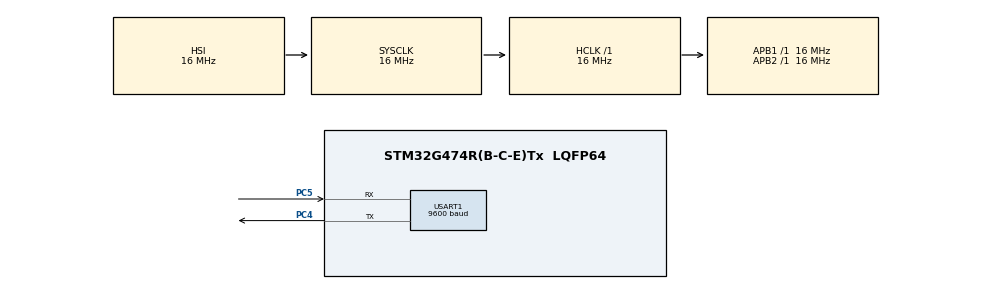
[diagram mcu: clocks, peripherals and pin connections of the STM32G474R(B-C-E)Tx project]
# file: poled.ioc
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Mcu.Family=STM32G4
Mcu.Name=STM32G474R(B-C-E)Tx
Mcu.Package=LQFP64
NVIC.PriorityGroup=NVIC_PRIORITYGROUP_4
PA13.Mode=Serial_Wire
PA13.Signal=SYS_JTMS-SWDIO
PA14.Mode=Serial_Wire
PA14.Signal=SYS_JTCK-SWCLK
PC4.Mode=Asynchronous
PC4.Signal=USART1_TX
PC5.Mode=Asynchronous
PC5.Signal=USART1_RX
ProjectManager.HeapSize=0x200
ProjectManager.StackSize=0x400
ProjectManager.TargetToolchain=MDK-ARM V5.32
RCC.AHBFreq_Value=16000000
RCC.APB1Freq_Value=16000000
RCC.APB1TimFreq_Value=16000000
RCC.APB2Freq_Value=16000000
RCC.APB2TimFreq_Value=16000000
RCC.CortexFreq_Value=16000000
RCC.EXTERNAL_CLOCK_VALUE=12288000
RCC.HCLKFreq_Value=16000000
RCC.HSE_VALUE=8000000
RCC.HSI48_VALUE=48000000
RCC.HSI_VALUE=16000000
RCC.LSE_VALUE=32768
RCC.SYSCLKFreq_VALUE=16000000
RCC.USBFreq_Value=64000000
RCC.VCOOutputFreq_Value=128000000
USART1.BaudRate=9600
USART1.VirtualMode-Asynchronous=VM_ASYNC
VP_SYS_VS_DBSignals.Mode=DisableDeadBatterySignals
board=custom

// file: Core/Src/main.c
/* USER CODE BEGIN Header */
/**
  ******************************************************************************
  * @file           : main.c
  * @brief          : Main program body
  ******************************************************************************
  * @attention
  *
  * Copyright (c) 2025 STMicroelectronics.
  * All rights reserved.
  *
  * This software is licensed under terms that can be found in the LICENSE file
  * in the root directory of this software component.
  * If no LICENSE file comes with this software, it is provided AS-IS.
  *
  ******************************************************************************
  */
/* USER CODE END Header */
#include "main.h"
#include "usart.h"
#include "gpio.h"

/* USER CODE BEGIN Includes */
#include "math.h"
#include <stdio.h>

/* USER CODE END Includes */

void SystemClock_Config(void);

/* USER CODE BEGIN 0 */
int fputc(int ch, FILE *f){
uint8_t temp[1] = {ch};
HAL_UART_Transmit(&huart1, temp, 1, 2);//huart1��Ҫ������������޸�
return ch;
}

////////////////////////////////////////////////////////////////////////////////////////////
int i;
int test_num = 0;
float test_float = 0;
void HMI_send_string(char* name, char* showdata)
{
    // printf("t0.txt=\"%d\"\xff\xff\xff", num);
    printf("%s=\"%s\"\xff\xff\xff", name, showdata);
}
void HMI_send_number(char* name, int num)
{
    // printf("t0.txt=\"%d\"\xff\xff\xff", num);
    printf("%s=%d\xff\xff\xff", name, num);
}
void HMI_send_float(char* name, float num)
{
    // printf("t0.txt=\"%d\"\xff\xff\xff", num);
    printf("%s=%d\xff\xff\xff", name, (int)(num * 100));
}
void HMI_Wave(char* name, int ch, int val)
{
    printf("add %s,%d,%d\xff\xff\xff", name, ch, val);
}
/* USER CODE END 0 */

int main(void)
{

  /* MCU Configuration--------------------------------------------------------*/

  /* Reset of all peripherals, Initializes the Flash interface and the Systick. */
  HAL_Init();

  /* Configure the system clock */
  SystemClock_Config();

  /* Initialize all configured peripherals */
  MX_GPIO_Init();
  MX_USART1_UART_Init();

  /* Infinite loop */
  while (1)
  {
	HMI_send_string("t0.txt", "1234");

	  int sin_data[255];
    for (i = 0; i < 255; i++)
		{
			sin_data[i] = (int)((sin((i + 1) * 3.14 / 50) + 1) * 90);
			HMI_Wave("s0.id", 0, sin_data[i]);
		}

  }
}

void SystemClock_Config(void)
{
  RCC_OscInitTypeDef RCC_OscInitStruct = {0};
  RCC_ClkInitTypeDef RCC_ClkInitStruct = {0};

  /** Configure the main internal regulator output voltage
  */
  HAL_PWREx_ControlVoltageScaling(PWR_REGULATOR_VOLTAGE_SCALE1);

  /** Initializes the RCC Oscillators according to the specified parameters
  * in the RCC_OscInitTypeDef structure.
  */
  RCC_OscInitStruct.OscillatorType = RCC_OSCILLATORTYPE_HSI;
  RCC_OscInitStruct.HSIState = RCC_HSI_ON;
  RCC_OscInitStruct.HSICalibrationValue = RCC_HSICALIBRATION_DEFAULT;
  RCC_OscInitStruct.PLL.PLLState = RCC_PLL_NONE;
  if (HAL_RCC_OscConfig(&RCC_OscInitStruct) != HAL_OK)
  {
    Error_Handler();
  }

  /** Initializes the CPU, AHB and APB buses clocks
  */
  RCC_ClkInitStruct.ClockType = RCC_CLOCKTYPE_HCLK|RCC_CLOCKTYPE_SYSCLK
                              |RCC_CLOCKTYPE_PCLK1|RCC_CLOCKTYPE_PCLK2;
  RCC_ClkInitStruct.SYSCLKSource = RCC_SYSCLKSOURCE_HSI;
  RCC_ClkInitStruct.AHBCLKDivider = RCC_SYSCLK_DIV1;
  RCC_ClkInitStruct.APB1CLKDivider = RCC_HCLK_DIV1;
  RCC_ClkInitStruct.APB2CLKDivider = RCC_HCLK_DIV1;

  if (HAL_RCC_ClockConfig(&RCC_ClkInitStruct, FLASH_LATENCY_0) != HAL_OK)
  {
    Error_Handler();
  }
}

void Error_Handler(void)
{
  __disable_irq();
  while (1)
  {
  }
}
